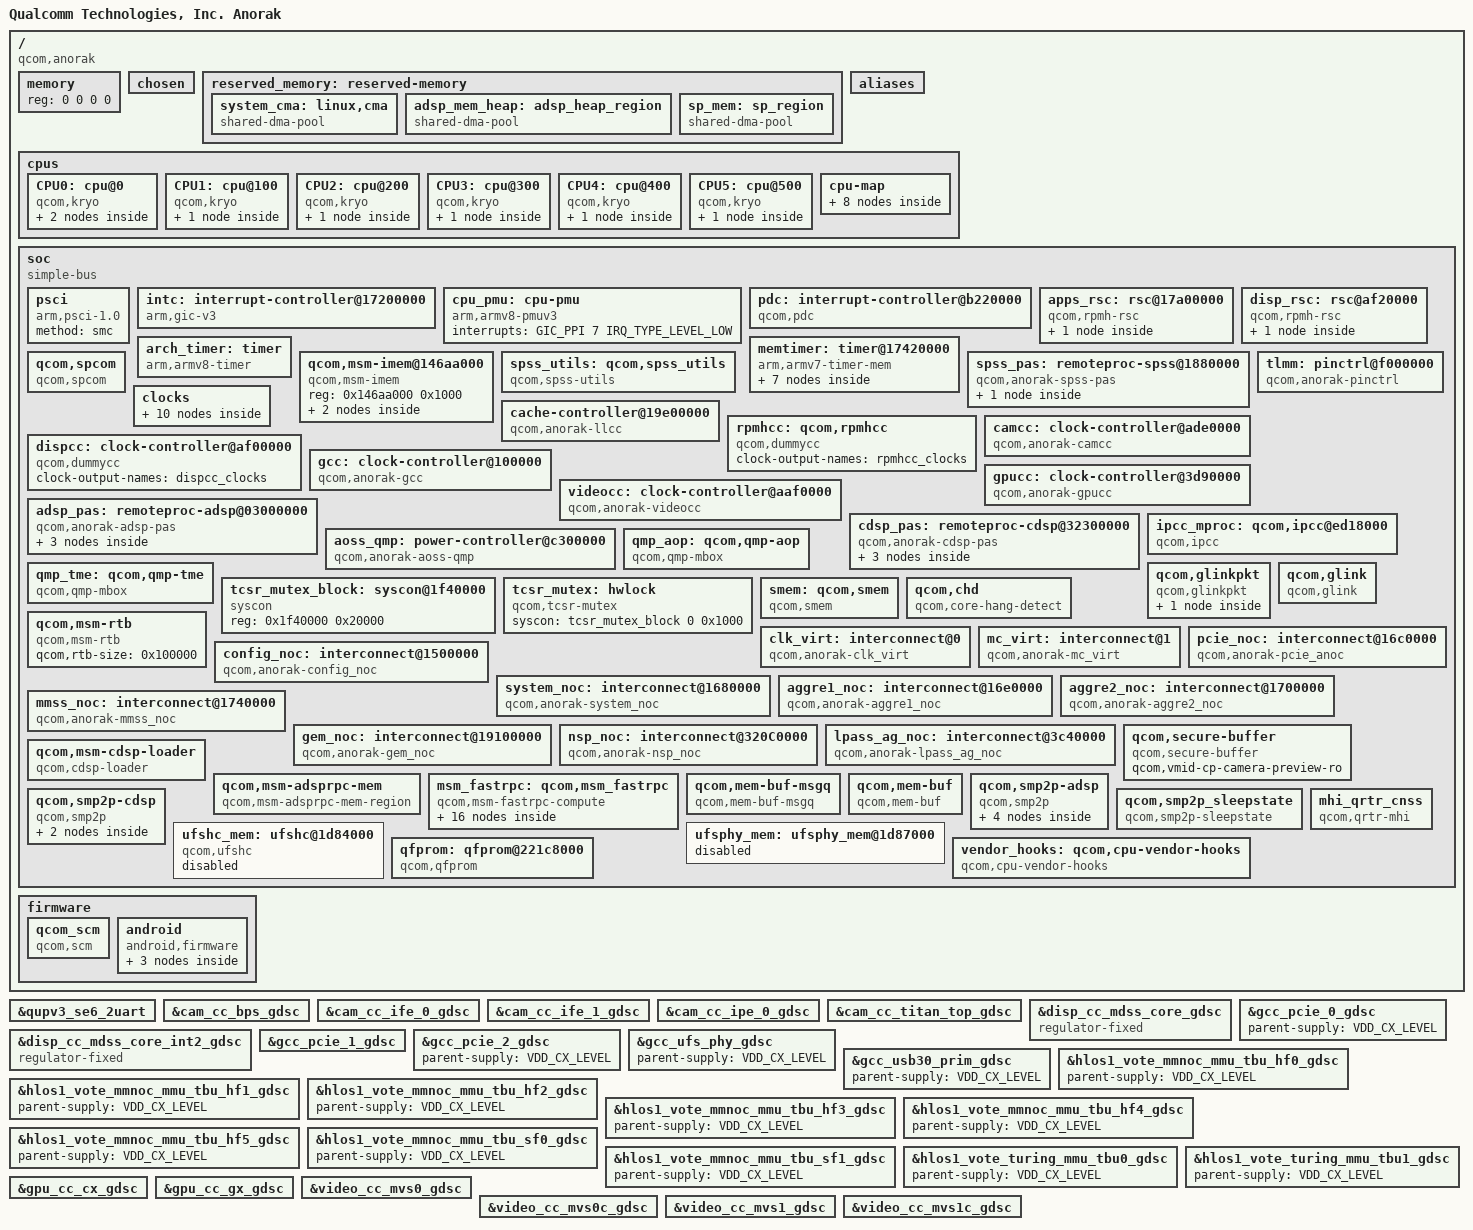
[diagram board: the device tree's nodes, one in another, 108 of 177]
#include <dt-bindings/clock/qcom,rpmh.h>
#include <dt-bindings/clock/qcom,camcc-anorak.h>
#include <dt-bindings/clock/qcom,dispcc-anorak.h>
#include <dt-bindings/clock/qcom,gcc-anorak.h>
#include <dt-bindings/clock/qcom,gpucc-anorak.h>
#include <dt-bindings/clock/qcom,videocc-anorak.h>
#include <dt-bindings/interrupt-controller/arm-gic.h>
#include <dt-bindings/interconnect/qcom,icc.h>
#include <dt-bindings/interconnect/qcom,anorak.h>
#include <dt-bindings/soc/qcom,ipcc.h>
#include <dt-bindings/soc/qcom,rpmh-rsc.h>
#include <dt-bindings/gpio/gpio.h>
#include <dt-bindings/regulator/qcom,rpmh-regulator-levels.h>

/ {
	model = "Qualcomm Technologies, Inc. Anorak";
	compatible = "qcom,anorak";
	qcom,msm-id = <549 0x10000>;
	interrupt-parent = <&intc>;

	#address-cells = <2>;
	#size-cells = <2>;
	memory { device_type = "memory"; reg = <0 0 0 0>; };


	chosen: chosen {
		bootargs = "console=ttyMSM0,115200n8 earlycon=msm_geni_serial,0x00998000 loglevel=8 log_buf_len=256K kernel.panic_on_rcu_stall=1 loop.max_part=7 service_locator.enable=1 msm_rtb.filter=0x237 allow_mismatched_32bit_el0 kasan=off rcupdate.rcu_expedited=1 rcu_nocbs=0-5 ftrace_dump_on_oops pstore.compress=none kpti=off swiotlb=noforce cgroup.memory=nokmem,nosocket allow_file_spec_access disable_dma32=on";
	};

	reserved_memory: reserved-memory { };

	aliases {
		ufshc1 = &ufshc_mem; /* Embedded UFS Slot */
		serial0 = &qupv3_se6_2uart;
	};

	cpus {
		#address-cells = <2>;
		#size-cells = <0>;

		CPU0: cpu@0 {
			device_type = "cpu";
			compatible = "qcom,kryo";
			reg = <0x0 0x0>;
			enable-method = "psci";
			next-level-cache = <&L2_0>;
			L2_0: l2-cache {
			      compatible = "arm,arch-cache";
			      cache-level = <2>;
			      next-level-cache = <&L3_0>;

				L3_0: l3-cache {
					compatible = "arm,arch-cache";
					cache-level = <3>;
				};
			};
		};

		CPU1: cpu@100 {
			device_type = "cpu";
			compatible = "qcom,kryo";
			reg = <0x0 0x100>;
			enable-method = "psci";
			next-level-cache = <&L2_1>;
			L2_1: l2-cache {
			      compatible = "arm,arch-cache";
			      cache-level = <2>;
			      next-level-cache = <&L3_0>;
			};

		};

		CPU2: cpu@200 {
			device_type = "cpu";
			compatible = "qcom,kryo";
			reg = <0x0 0x200>;
			enable-method = "psci";
			next-level-cache = <&L2_2>;
			L2_2: l2-cache {
			      compatible = "arm,arch-cache";
			      cache-level = <2>;
			      next-level-cache = <&L3_0>;
			};
		};

		CPU3: cpu@300 {
			device_type = "cpu";
			compatible = "qcom,kryo";
			reg = <0x0 0x300>;
			enable-method = "psci";
			next-level-cache = <&L2_3>;
			L2_3: l2-cache {
			      compatible = "arm,arch-cache";
			      cache-level = <2>;
			      next-level-cache = <&L3_0>;
			};

		};

		CPU4: cpu@400 {
			device_type = "cpu";
			compatible = "qcom,kryo";
			reg = <0x0 0x400>;
			enable-method = "psci";
			next-level-cache = <&L2_4>;
			L2_4: l2-cache {
				compatible = "arm,arch-cache";
				cache-level = <2>;
				next-level-cache = <&L3_0>;
			};
		};

		CPU5: cpu@500 {
			device_type = "cpu";
			compatible = "qcom,kryo";
			reg = <0x0 0x500>;
			enable-method = "psci";
			next-level-cache = <&L2_5>;
			L2_5: l2-cache {
				compatible = "arm,arch-cache";
				cache-level = <2>;
				next-level-cache = <&L3_0>;
			};
		};

		cpu-map {
			cluster0 {
				core0 {
					cpu = <&CPU0>;
				};

				core1 {
					cpu = <&CPU1>;
				};
			};

			cluster1 {
				core0 {
					cpu = <&CPU2>;
				};

				core1 {
					cpu = <&CPU3>;
				};

				core2 {
					cpu = <&CPU4>;
				};

				core3 {
					cpu = <&CPU5>;
				};
			};
		};
	};

	soc: soc { };

	firmware: firmware { };
};

#include "anorak-reserved-memory.dtsi"

&reserved_memory {
	#address-cells = <2>;
	#size-cells = <2>;
	ranges;

	/* global autoconfigured region for contiguous allocations */
	system_cma: linux,cma {
		compatible = "shared-dma-pool";
		alloc-ranges = <0x0 0x00000000 0x0 0xffffffff>;
		reusable;
		alignment = <0x0 0x400000>;
		size = <0x0 0x2000000>;
		linux,cma-default;
	};

	adsp_mem_heap: adsp_heap_region {
		compatible = "shared-dma-pool";
		alloc-ranges = <0x0 0x00000000 0x0 0xffffffff>;
		reusable;
		alignment = <0x0 0x400000>;
		size = <0x0 0xC00000>;
	};

	sp_mem: sp_region {  /* SPSS-HLOS ION shared mem */
		compatible = "shared-dma-pool";
		alloc-ranges = <0x0 0x00000000 0x0 0xffffffff>;
		reusable;
		alignment = <0x0 0x400000>;
		size = <0x0 0x1000000>;
	};
};

&firmware {
	qcom_scm {
		compatible = "qcom,scm";
	};

	android {
		compatible = "android,firmware";
		vbmeta {
			compatible = "android,vbmeta";
			parts = "vbmeta,boot,system,vendor,dtbo,recovery";
		};

		fstab {
			compatible = "android,fstab";
			vendor {
				compatible = "android,vendor";
				dev = "/dev/block/platform/soc/1d84000.ufshc/by-name/vendor";
				type = "ext4";
				mnt_flags = "ro,barrier=1,discard";
				fsmgr_flags = "wait,slotselect";
				status = "ok";
			};
		};
	};
};

&soc {
	#address-cells = <1>;
	#size-cells = <1>;
	ranges = <0 0 0 0xffffffff>;
	compatible = "simple-bus";

	psci {
		compatible = "arm,psci-1.0";
		method = "smc";
	};

	intc: interrupt-controller@17200000 {
		compatible = "arm,gic-v3";
		#interrupt-cells = <3>;
		interrupt-controller;
		#redistributor-regions = <1>;
		redistributor-stride = <0x0 0x20000>;
		reg = <0x17200000 0x10000>,	/* GICD */
		      <0x17260000 0x100000>;	/* GICR * 8 */
		interrupts = <GIC_PPI 9 IRQ_TYPE_LEVEL_LOW>;
	};

	cpu_pmu: cpu-pmu {
		compatible = "arm,armv8-pmuv3";
		interrupts = <GIC_PPI 7 IRQ_TYPE_LEVEL_LOW>;
	};

	pdc: interrupt-controller@b220000 {
		compatible = "qcom,pdc";
		reg = <0xb220000 0x30000>, <0x174000f0 0x64>;
		reg-names = "pdc-interrupt-base", "apss-shared-spi-cfg";
		qcom,pdc-ranges = <0 480 12>, <14 494 24>, <40 520 54>,
				  <94 609 31>, <125 63 1>, <126 716 12>;
		#interrupt-cells = <2>;
		interrupt-parent = <&intc>;
		interrupt-controller;
	};

	apps_rsc: rsc@17a00000 {
		label = "apps_rsc";
		compatible = "qcom,rpmh-rsc";
		reg = <0x17a00000 0x10000>,
		      <0x17a10000 0x10000>,
		      <0x17a20000 0x10000>,
		      <0x17a30000 0x10000>;
		reg-names = "drv-0", "drv-1", "drv-2", "drv-3";
		interrupts = <GIC_SPI 3 IRQ_TYPE_LEVEL_HIGH>,
			     <GIC_SPI 4 IRQ_TYPE_LEVEL_HIGH>,
			     <GIC_SPI 5 IRQ_TYPE_LEVEL_HIGH>;
			     /* No interrupt into GIC for DRV3 */
		qcom,tcs-offset = <0xd00>;
		qcom,drv-id = <2>;
		qcom,tcs-config = <ACTIVE_TCS    2>,
				  <SLEEP_TCS     3>,
				  <WAKE_TCS      3>,
				  <FAST_PATH_TCS 0>,
				  <CONTROL_TCS   0>; /* PDC wakeup values will be written from TZ */

		apps_bcm_voter: bcm_voter {
			compatible = "qcom,bcm-voter";
		};
	};

	disp_rsc: rsc@af20000 {
		label = "disp_rsc";
		compatible = "qcom,rpmh-rsc";
		reg = <0xaf20000 0x10000>;
		reg-names = "drv-0";
		interrupts = <GIC_SPI 129 IRQ_TYPE_LEVEL_HIGH>;
		clocks = <&dispcc DISP_CC_MDSS_RSCC_AHB_CLK>;
		qcom,tcs-offset = <0x1c00>;
		qcom,drv-id = <0>;
		qcom,tcs-config = <ACTIVE_TCS    0>,
				  <SLEEP_TCS     1>,
				  <WAKE_TCS      1>,
				  <CONTROL_TCS   0>,
				  <FAST_PATH_TCS 0>;

		disp_bcm_voter: bcm_voter {
			compatible = "qcom,bcm-voter";
			qcom,tcs-wait = <QCOM_ICC_TAG_AMC>;
		};
	};

	arch_timer: timer {
		compatible = "arm,armv8-timer";
		interrupts = <GIC_PPI 13 (GIC_CPU_MASK_SIMPLE(8) | IRQ_TYPE_LEVEL_LOW)>,
			     <GIC_PPI 14 (GIC_CPU_MASK_SIMPLE(8) | IRQ_TYPE_LEVEL_LOW)>,
			     <GIC_PPI 11 (GIC_CPU_MASK_SIMPLE(8) | IRQ_TYPE_LEVEL_LOW)>,
			     <GIC_PPI 12 (GIC_CPU_MASK_SIMPLE(8) | IRQ_TYPE_LEVEL_LOW)>;
		clock-frequency = <19200000>;
	};

	memtimer: timer@17420000 {
		#address-cells = <1>;
		#size-cells = <1>;
		ranges;
		compatible = "arm,armv7-timer-mem";
		reg = <0x17420000 0x1000>;
		clock-frequency = <19200000>;

		frame@17421000 {
			frame-number = <0>;
			interrupts = <GIC_SPI 8 IRQ_TYPE_LEVEL_HIGH>,
				     <GIC_SPI 6 IRQ_TYPE_LEVEL_HIGH>;
			reg = <0x17421000 0x1000>,
			      <0x17422000 0x1000>;
		};

		frame@17423000 {
			frame-number = <1>;
			interrupts = <GIC_SPI 9 IRQ_TYPE_LEVEL_HIGH>;
			reg = <0x17423000 0x1000>;
			status = "disabled";
		};

		frame@17425000 {
			frame-number = <2>;
			interrupts = <GIC_SPI 10 IRQ_TYPE_LEVEL_HIGH>;
			reg = <0x17425000 0x1000>;
			status = "disabled";
		};

		frame@17427000 {
			frame-number = <3>;
			interrupts = <GIC_SPI 11 IRQ_TYPE_LEVEL_HIGH>;
			reg = <0x17427000 0x1000>;
			status = "disabled";
		};

		frame@17429000 {
			frame-number = <4>;
			interrupts = <GIC_SPI 12 IRQ_TYPE_LEVEL_HIGH>;
			reg = <0x17429000 0x1000>;
			status = "disabled";
		};

		frame@1742b000 {
			frame-number = <5>;
			interrupts = <GIC_SPI 13 IRQ_TYPE_LEVEL_HIGH>;
			reg = <0x1742b000 0x1000>;
			status = "disabled";
		};

		frame@1742d000 {
			frame-number = <6>;
			interrupts = <GIC_SPI 14 IRQ_TYPE_LEVEL_HIGH>;
			reg = <0x1742d000 0x1000>;
			status = "disabled";
		};
	};

	qcom,msm-imem@146aa000 {
		compatible = "qcom,msm-imem";
		reg = <0x146aa000 0x1000>;
		ranges = <0x0 0x146aa000 0x1000>;
		#address-cells = <1>;
		#size-cells = <1>;

		pil@94c {
			compatible = "qcom,pil-reloc-info";
			reg = <0x94c 0xc8>;
		};

		pil@6dc {
			compatible = "qcom,msm-imem-pil-disable-timeout";
			reg = <0x6dc 0x4>;
		};
	};

	/* PIL spss node - for loading Secure Processor */
	spss_pas: remoteproc-spss@1880000 {
		compatible = "qcom,anorak-spss-pas";
		ranges;
		reg = <0x188101c 0x4>,
		      <0x1881024 0x4>,
		      <0x1881028 0x4>,
		      <0x188103c 0x4>,
		      <0x1881100 0x4>,
		      <0x1882014 0x4>;
		reg-names = "sp2soc_irq_status", "sp2soc_irq_clr", "sp2soc_irq_mask",
			    "rmb_err", "rmb_general_purpose", "rmb_err_spare2";
		interrupts = <0 352 1>;

		cx-supply = <&VDD_CX_LEVEL>;
		cx-uV-uA = <RPMH_REGULATOR_LEVEL_TURBO 100000>;

		clocks = <&rpmhcc RPMH_CXO_CLK>;
		clock-names = "xo";
		qcom,proxy-clock-names = "xo";
		status = "ok";

		memory-region = <&spss_region_mem>;
		qcom,spss-scsr-bits = <24 25>;
		qcom,extra-size = <4096>;

		interconnects = <&aggre2_noc MASTER_CRYPTO &mc_virt SLAVE_EBI1>;
		interconnect-names = "crypto_ddr";

		glink-edge {
			qcom,remote-pid = <8>;
			mboxes = <&ipcc_mproc IPCC_CLIENT_SPSS
				  IPCC_MPROC_SIGNAL_GLINK_QMP>;
			mbox-names = "spss_spss";
			interrupt-parent = <&ipcc_mproc>;
			interrupts = <IPCC_CLIENT_SPSS
				      IPCC_MPROC_SIGNAL_GLINK_QMP
				      IRQ_TYPE_EDGE_RISING>;

			reg = <0x1885008 0x8>,
			      <0x1885010 0x4>;
			reg-names = "qcom,spss-addr",
				    "qcom,spss-size";

			label = "spss";
			qcom,glink-label = "spss";
		};
	};

	qcom,spcom {
		compatible = "qcom,spcom";

		qcom,rproc-handle = <&spss_pas>;
		qcom,boot-enabled;
		/* predefined channels, remote side is server */
		qcom,spcom-ch-names = "sp_kernel", "sp_ssr";
		/* sp2soc rmb shared register physical address and bmsk */
		qcom,spcom-sp2soc-rmb-reg-addr = <0x01881020>;
		qcom,spcom-sp2soc-rmb-initdone-bit = <24>;
		qcom,spcom-sp2soc-rmb-pbldone-bit = <25>;
		/* soc2sp rmb shared register physical address */
		qcom,spcom-soc2sp-rmb-reg-addr = <0x01881030>;
		qcom,spcom-soc2sp-rmb-sp-ssr-bit = <0>;
		status = "ok";
	};

	spss_utils: qcom,spss_utils {
		compatible = "qcom,spss-utils";
		/* spss fuses physical address */
		qcom,rproc-handle = <&spss_pas>;
		qcom,spss-fuse1-addr = <0x221C8214>;
		qcom,spss-fuse1-bit = <8>;
		qcom,spss-fuse2-addr = <0x221C8214>;
		qcom,spss-fuse2-bit = <7>;
		qcom,spss-dev-firmware-name  = "spss1d.mdt";  /* 8 chars max */
		qcom,spss-test-firmware-name = "spss1t.mdt";  /* 8 chars max */
		qcom,spss-prod-firmware-name = "spss1p.mdt";  /* 8 chars max */
		qcom,spss-debug-reg-addr = <0x01886020>;
		qcom,spss-debug-reg-addr1 = <0x01888020>;
		qcom,spss-debug-reg-addr3 = <0x0188C020>;
		qcom,spss-emul-type-reg-addr = <0x01fc8004>;
		pil-mem = <&spss_region_mem>;
		qcom,pil-size = <0x0F0000>; // padding to 960KB
		status = "ok";
	};

	tlmm: pinctrl@f000000 {
		compatible = "qcom,anorak-pinctrl";
		reg = <0xf000000 0x1000000>;
		interrupts = <GIC_SPI 208 IRQ_TYPE_LEVEL_HIGH>;
		gpio-controller;
		#gpio-cells = <2>;
		interrupt-controller;
		#interrupt-cells = <2>;
		wakeup-parent = <&pdc>;
	};

	clocks {
		xo_board: xo_board {
			compatible = "fixed-clock";
			clock-frequency = <76800000>;
			clock-output-names = "xo_board";
			#clock-cells = <0>;
		};

		sleep_clk: sleep_clk {
			compatible = "fixed-clock";
			clock-frequency = <32000>;
			clock-output-names = "sleep_clk";
			#clock-cells = <0>;
		};

		pcie_0_pipe_clk: pcie_0_pipe_clk {
			compatible = "fixed-clock";
			clock-frequency = <1000>;
			clock-output-names = "pcie_0_pipe_clk";
			#clock-cells = <0>;
		};

		pcie_1_pipe_clk: pcie_1_pipe_clk {
			compatible = "fixed-clock";
			clock-frequency = <1000>;
			clock-output-names = "pcie_1_pipe_clk";
			#clock-cells = <0>;
		};

		pcie_2_phy_aux_clk: pcie_2_phy_aux_clk {
			compatible = "fixed-clock";
			clock-frequency = <1000>;
			clock-output-names = "pcie_2_phy_aux_clk";
			#clock-cells = <0>;
		};

		pcie_2_pipe_clk: pcie_2_pipe_clk {
			compatible = "fixed-clock";
			clock-frequency = <1000>;
			clock-output-names = "pcie_2_pipe_clk";
			#clock-cells = <0>;
		};

		ufs_phy_rx_symbol_0_clk: ufs_phy_rx_symbol_0_clk {
			compatible = "fixed-clock";
			clock-frequency = <1000>;
			clock-output-names = "ufs_phy_rx_symbol_0_clk";
			#clock-cells = <0>;
		};

		ufs_phy_rx_symbol_1_clk: ufs_phy_rx_symbol_1_clk {
			compatible = "fixed-clock";
			clock-frequency = <1000>;
			clock-output-names = "ufs_phy_rx_symbol_1_clk";
			#clock-cells = <0>;
		};

		ufs_phy_tx_symbol_0_clk: ufs_phy_tx_symbol_0_clk {
			compatible = "fixed-clock";
			clock-frequency = <1000>;
			clock-output-names = "ufs_phy_tx_symbol_0_clk";
			#clock-cells = <0>;
		};

		usb3_phy_wrapper_gcc_usb30_pipe_clk: usb3_phy_wrapper_gcc_usb30_pipe_clk {
			compatible = "fixed-clock";
			clock-frequency = <1000>;
			clock-output-names = "usb3_phy_wrapper_gcc_usb30_pipe_clk";
			#clock-cells = <0>;
		};
	};

	cache-controller@19e00000 {
		compatible = "qcom,anorak-llcc", "qcom,llcc-v41";
		reg = <0x19e00000 0x800000>, <0x1a600000 0x200000>;
		reg-names = "llcc_base", "llcc_broadcast_base";
		interrupts = <GIC_SPI 266 IRQ_TYPE_LEVEL_HIGH>;
		cap-based-alloc-and-pwr-collapse;
	};

	rpmhcc: qcom,rpmhcc {
		compatible = "qcom,dummycc";
		clock-output-names = "rpmhcc_clocks";
		#clock-cells = <1>;
		#reset-cells = <1>;
	};

	camcc: clock-controller@ade0000 {
		compatible = "qcom,anorak-camcc", "syscon";
		reg = <0xade0000 0x20000>;
		reg-name = "cc_base";
		vdd_mm-supply = <&VDD_MM_LEVEL>;
		vdd_mxa-supply = <&VDD_MXA_LEVEL>;
		vdd_mxc-supply = <&VDD_MXC_LEVEL>;
		clocks = <&rpmhcc RPMH_CXO_CLK>,
			<&sleep_clk>,
			<&gcc GCC_CAMERA_AHB_CLK>;
		clock-names = "bi_tcxo",
			"sleep_clk","iface";
		clock-output-names = "camcc_clocks";
		#clock-cells = <1>;
		#reset-cells = <1>;
	};

	dispcc: clock-controller@af00000 {
		compatible = "qcom,dummycc";
		clock-output-names = "dispcc_clocks";
		#clock-cells = <1>;
		#reset-cells = <1>;
	};

	gcc: clock-controller@100000 {
		compatible = "qcom,anorak-gcc", "syscon";
		reg = <0x100000 0x1f4200>;
		reg-name = "cc_base";
		vdd_cx-supply = <&VDD_CX_LEVEL>;
		vdd_mxa-supply = <&VDD_MXA_LEVEL>;
		clocks = <&rpmhcc RPMH_CXO_CLK>, <&sleep_clk>,
			<&pcie_0_pipe_clk>, <&pcie_1_pipe_clk>,
			<&pcie_2_phy_aux_clk>, <&pcie_2_pipe_clk>,
			<&ufs_phy_rx_symbol_0_clk>, <&ufs_phy_rx_symbol_1_clk>,
			<&ufs_phy_tx_symbol_0_clk>, <&usb3_phy_wrapper_gcc_usb30_pipe_clk>;
		clock-names = "bi_tcxo", "sleep_clk",
			"pcie_0_pipe_clk", "pcie_1_pipe_clk",
			"pcie_2_phy_aux_clk", "pcie_2_pipe_clk",
			"ufs_phy_rx_symbol_0_clk", "ufs_phy_rx_symbol_1_clk",
			"ufs_phy_tx_symbol_0_clk", "usb3_phy_wrapper_gcc_usb30_pipe_clk";
		#clock-cells = <1>;
		#reset-cells = <1>;
	};

	gpucc: clock-controller@3d90000 {
		compatible = "qcom,anorak-gpucc", "syscon";
		reg = <0x3d90000 0xa000>;
		reg-name = "cc_base";
		vdd_cx-supply = <&VDD_CX_LEVEL>;
		vdd_mxa-supply = <&VDD_MXA_LEVEL>;
		vdd_mxc-supply = <&VDD_MXC_LEVEL>;
		clocks = <&rpmhcc RPMH_CXO_CLK>, <&gcc GCC_GPU_GPLL0_CLK_SRC>,
			<&gcc GCC_GPU_GPLL0_DIV_CLK_SRC>;
		clock-names = "bi_tcxo", "gpll0_out_main",
			"gpll0_out_main_div";
		#clock-cells = <1>;
		#reset-cells = <1>;
	};

	videocc: clock-controller@aaf0000 {
		compatible = "qcom,anorak-videocc", "syscon";
		reg = <0xaaf0000 0x10000>;
		reg-name = "cc_base";
		vdd_mm-supply = <&VDD_MM_LEVEL>;
		vdd_mxc-supply = <&VDD_MXC_LEVEL>;
		clocks = <&rpmhcc RPMH_CXO_CLK>,
			<&sleep_clk>,
			<&gcc GCC_VIDEO_AHB_CLK>;
		clock-names = "bi_tcxo", "sleep_clk",
			"iface";
		#clock-cells = <1>;
		#reset-cells = <1>;
	};

	adsp_pas: remoteproc-adsp@03000000 {
		compatible = "qcom,anorak-adsp-pas";
		reg = <0x03000000 0x10000>;

		cx-supply = <&VDD_LPI_CX_LEVEL>;
		cx-uV-uA = <RPMH_REGULATOR_LEVEL_TURBO 0>;
		mx-supply = <&VDD_LPI_MX_LEVEL>;
		mx-uV-uA = <RPMH_REGULATOR_LEVEL_TURBO 0>;
		reg-names = "cx", "mx";

		clocks = <&rpmhcc RPMH_CXO_CLK>;
		clock-names = "xo";

		qcom,qmp = <&aoss_qmp>;

		memory-region = <&adsp_mem>;

		/* Inputs from ssc */
		interrupts-extended = <&pdc 6 IRQ_TYPE_EDGE_RISING>,
					<&adsp_smp2p_in 0 0>,
					<&adsp_smp2p_in 2 0>,
					<&adsp_smp2p_in 1 0>,
					<&adsp_smp2p_in 3 0>;

		interrupt-names = "wdog",
				"fatal",
				"handover",
				"ready",
				"stop-ack";

		/* Outputs to turing */
		qcom,smem-states = <&adsp_smp2p_out 0>;
		qcom,smem-state-names = "stop";

		status = "ok";

		glink_edge: glink-edge {
			qcom,remote-pid = <2>;
			transport = "smem";
			mboxes = <&ipcc_mproc IPCC_CLIENT_LPASS
			IPCC_MPROC_SIGNAL_GLINK_QMP>;
			mbox-names = "adsp_smem";
			interrupt-parent = <&ipcc_mproc>;
			interrupts = <IPCC_CLIENT_LPASS
					IPCC_MPROC_SIGNAL_GLINK_QMP
					IRQ_TYPE_EDGE_RISING>;

			label = "adsp";
			qcom,glink-label = "lpass";

			qcom,adsp_qrtr {
				qcom,glink-channels = "IPCRTR";
				qcom,intents = <0x800  5
						0x2000 3
						0x4400 2>;
			};

			qcom,msm_fastrpc_rpmsg {
					compatible = "qcom,msm-fastrpc-rpmsg";
					qcom,glink-channels = "fastrpcglink-apps-dsp";
					qcom,intents = <0x64 64>;
			};
		};
	};

	cdsp_pas: remoteproc-cdsp@32300000 {
		compatible = "qcom,anorak-cdsp-pas";
		reg = <0x32300000 0x10000>;

		cx-supply = <&VDD_CX_LEVEL>;
		cx-uV-uA = <RPMH_REGULATOR_LEVEL_TURBO 100000>;
		mx-supply = <&VDD_MXC_LEVEL>;
		mx-uV-uA = <RPMH_REGULATOR_LEVEL_TURBO 100000>;
		reg-names = "cx","mx","nsp";
		clocks = <&rpmhcc RPMH_CXO_CLK>;
		clock-names = "xo";

		qcom,qmp = <&aoss_qmp>;

		memory-region = <&cdsp_mem>;

		/* Inputs from turing */
		interrupts-extended = <&intc GIC_SPI 578 IRQ_TYPE_EDGE_RISING>,
					<&cdsp_smp2p_in 0 0>,
					<&cdsp_smp2p_in 2 0>,
					<&cdsp_smp2p_in 1 0>,
					<&cdsp_smp2p_in 3 0>;

		interrupt-names = "wdog",
				"fatal",
				"handover",
				"ready",
				"stop-ack";

		/* Outputs to turing */
		qcom,smem-states = <&cdsp_smp2p_out 0>;
		qcom,smem-state-names = "stop";
		status = "ok";

		glink-edge {
			qcom,remote-pid = <5>;
			transport = "smem";
			mboxes = <&ipcc_mproc IPCC_CLIENT_CDSP
					  IPCC_MPROC_SIGNAL_GLINK_QMP>;
			mbox-names = "cdsp_smem";
			interrupt-parent = <&ipcc_mproc>;
			interrupts = <IPCC_CLIENT_CDSP
				  IPCC_MPROC_SIGNAL_GLINK_QMP
				  IRQ_TYPE_EDGE_RISING>;

			label = "cdsp";
			qcom,glink-label = "cdsp";

			qcom,cdsp_qrtr {
				qcom,glink-channels = "IPCRTR";
				qcom,intents = <0x800  5
						0x2000 3
						0x4400 2>;
			};

			qcom,msm_fastrpc_rpmsg {
				compatible = "qcom,msm-fastrpc-rpmsg";
				qcom,glink-channels = "fastrpcglink-apps-dsp";
				qcom,intents = <0x64 64>;
			};
		};
	};

	ipcc_mproc: qcom,ipcc@ed18000 {
		compatible = "qcom,ipcc";
		reg = <0x408000 0x1000>;
		interrupts = <GIC_SPI 229 IRQ_TYPE_LEVEL_HIGH>;
		interrupt-controller;
		#interrupt-cells = <3>;
		#mbox-cells = <2>;
	};

	aoss_qmp: power-controller@c300000 {
		compatible = "qcom,anorak-aoss-qmp";
		reg = <0xc300000 0x400>;
		interrupt-parent = <&ipcc_mproc>;
		interrupts = <IPCC_CLIENT_AOP
				IPCC_MPROC_SIGNAL_GLINK_QMP
				IRQ_TYPE_EDGE_RISING>;
		mboxes = <&ipcc_mproc IPCC_CLIENT_AOP
		IPCC_MPROC_SIGNAL_GLINK_QMP>;

		#power-domain-cells = <1>;
		#clock-cells = <0>;
	};

	qmp_aop: qcom,qmp-aop {
		compatible = "qcom,qmp-mbox";
		qcom,qmp = <&aoss_qmp>;
		label = "aop";
		#mbox-cells = <1>;
	};

	qmp_tme: qcom,qmp-tme {
		compatible = "qcom,qmp-mbox";
		qcom,remote-pid = <14>;
		mboxes = <&ipcc_mproc IPCC_CLIENT_TME
				IPCC_MPROC_SIGNAL_GLINK_QMP>;
		mbox-names = "tme_qmp";
		interrupt-parent = <&ipcc_mproc>;
		interrupts = <IPCC_CLIENT_TME
				IPCC_MPROC_SIGNAL_GLINK_QMP
				IRQ_TYPE_EDGE_RISING>;

		label = "tme";
		qcom,early-boot;
		priority = <0>;
		mbox-desc-offset = <0x0>;
		#mbox-cells = <1>;
	};

	qcom,glinkpkt {
		compatible = "qcom,glinkpkt";

		qcom,glinkpkt-apr-apps2 {
			qcom,glinkpkt-edge = "adsp";
			qcom,glinkpkt-ch-name = "apr_apps2";
			qcom,glinkpkt-dev-name = "apr_apps2";
		};
	};

	qcom,glink {
		compatible = "qcom,glink";
	};

	tcsr_mutex_block: syscon@1f40000 {
		compatible = "syscon";
		reg = <0x1f40000 0x20000>;
	};

	tcsr_mutex: hwlock {
		compatible = "qcom,tcsr-mutex";
		syscon = <&tcsr_mutex_block 0 0x1000>;
		#hwlock-cells = <1>;
		};

	smem: qcom,smem {
		compatible = "qcom,smem";
		memory-region = <&smem_mem>;
		hwlocks = <&tcsr_mutex 3>;
	};

	qcom,chd {
		compatible = "qcom,core-hang-detect";
		label = "core";
		qcom,threshold-arr = <0x17800058 0x17810058 0x17820058 0x17830058 0x17840058 0x17850058>;
		qcom,config-arr =<0x17800060 0x17810060 0x17820060 0x17830060 0x17840060 0x17850060>;
	};

	qcom,msm-rtb {
		compatible = "qcom,msm-rtb";
		qcom,rtb-size = <0x100000>;
	};

	clk_virt: interconnect@0 {
		compatible = "qcom,anorak-clk_virt";
		#interconnect-cells = <1>;
		qcom,bcm-voter-names = "hlos";
		qcom,bcm-voters = <&apps_bcm_voter>;
	};

	mc_virt: interconnect@1 {
		compatible = "qcom,anorak-mc_virt";
		#interconnect-cells = <1>;
		qcom,bcm-voter-names = "hlos", "disp";
		qcom,bcm-voters = <&apps_bcm_voter>, <&disp_bcm_voter>;
	};

	config_noc: interconnect@1500000 {
		reg = <0x1500000 0x13080>;
		compatible = "qcom,anorak-config_noc";
		#interconnect-cells = <1>;
		qcom,bcm-voter-names = "hlos";
		qcom,bcm-voters = <&apps_bcm_voter>;
	};

	system_noc: interconnect@1680000 {
		reg = <0x01680000 0x13080>;
		compatible = "qcom,anorak-system_noc";
		#interconnect-cells = <1>;
		qcom,bcm-voter-names = "hlos";
		qcom,bcm-voters = <&apps_bcm_voter>;
	};

	pcie_noc: interconnect@16c0000 {
		reg = <0x16C0000 0xC080>;
		compatible = "qcom,anorak-pcie_anoc";
		#interconnect-cells = <1>;
		qcom,bcm-voter-names = "hlos";
		qcom,bcm-voters = <&apps_bcm_voter>;
	};

	aggre1_noc: interconnect@16e0000 {
		reg = <0x16E0000 0x9080>;
		compatible = "qcom,anorak-aggre1_noc";
		#interconnect-cells = <1>;
		qcom,bcm-voter-names = "hlos";
		qcom,bcm-voters = <&apps_bcm_voter>;
	};

	aggre2_noc: interconnect@1700000 {
		reg = <0x1700000 0x15080>;
		compatible = "qcom,anorak-aggre2_noc";
		#interconnect-cells = <1>;
		qcom,bcm-voter-names = "hlos";
		qcom,bcm-voters = <&apps_bcm_voter>;
	};

	mmss_noc: interconnect@1740000 {
		reg = <0x01740000 0x1C100>;
		compatible = "qcom,anorak-mmss_noc";
		#interconnect-cells = <1>;
		qcom,bcm-voter-names = "hlos", "disp";
		qcom,bcm-voters = <&apps_bcm_voter>, <&disp_bcm_voter>;
	};

	gem_noc: interconnect@19100000 {
		reg = <0x19100000 0xA9080>;
		compatible = "qcom,anorak-gem_noc";
		#interconnect-cells = <1>;
		qcom,bcm-voter-names = "hlos", "disp";
		qcom,bcm-voters = <&apps_bcm_voter>, <&disp_bcm_voter>;
	};

	nsp_noc: interconnect@320C0000 {
		reg = <0x320C0000 0x10000>;
		compatible = "qcom,anorak-nsp_noc";
		#interconnect-cells = <1>;
		qcom,bcm-voter-names = "hlos";
		qcom,bcm-voters = <&apps_bcm_voter>;
	};

	lpass_ag_noc: interconnect@3c40000 {
		reg = <0x3c40000 0x17200>;
		compatible = "qcom,anorak-lpass_ag_noc";
		#interconnect-cells = <1>;
		qcom,bcm-voter-names = "hlos";
		qcom,bcm-voters = <&apps_bcm_voter>;
	};

	qcom,secure-buffer {
		compatible = "qcom,secure-buffer";
		qcom,vmid-cp-camera-preview-ro;
	};

	qcom,msm-cdsp-loader {
		compatible = "qcom,cdsp-loader";
		qcom,proc-img-to-load = "cdsp";
		qcom,rproc-handle = <&cdsp_pas>;
	};

	qcom,msm-adsprpc-mem {
		compatible = "qcom,msm-adsprpc-mem-region";
		memory-region = <&adsp_mem_heap>;
		restrict-access;
	};

	msm_fastrpc: qcom,msm_fastrpc {
		compatible = "qcom,msm-fastrpc-compute";
		qcom,adsp-remoteheap-vmid = <22 37>;
		qcom,fastrpc-adsp-audio-pdr;
		qcom,fastrpc-adsp-sensors-pdr;
		qcom,rpc-latency-us = <235>;
		qcom,fastrpc-gids = <2908>;
		qcom,qos-cores = <2>; /* its a gold+ cluster */

		qcom,msm_fastrpc_compute_cb1 {
			compatible = "qcom,msm-fastrpc-compute-cb";
			label = "cdsprpc-smd";
			iommus = <&apps_smmu 0x0961 0x0420>,
					 <&apps_smmu 0x2021 0x0560>;
			qcom,iommu-dma-addr-pool = <0x80000000 0x78000000>;
			qcom,iommu-faults = "stall-disable", "HUPCF";
			dma-coherent;
		};

		qcom,msm_fastrpc_compute_cb2 {
			compatible = "qcom,msm-fastrpc-compute-cb";
			label = "cdsprpc-smd";
			iommus = <&apps_smmu 0x0962 0x0400>,
					 <&apps_smmu 0x2022 0x0460>;
			qcom,iommu-dma-addr-pool = <0x80000000 0x78000000>;
			qcom,iommu-faults = "stall-disable", "HUPCF";
			dma-coherent;
		};

		qcom,msm_fastrpc_compute_cb3 {
			compatible = "qcom,msm-fastrpc-compute-cb";
			label = "cdsprpc-smd";
			iommus = <&apps_smmu 0x0963 0x0C60>,
					 <&apps_smmu 0x2023 0x0420>;
			qcom,iommu-dma-addr-pool = <0x80000000 0x78000000>;
			qcom,iommu-faults = "stall-disable", "HUPCF";
			dma-coherent;
		};

		qcom,msm_fastrpc_compute_cb4 {
			compatible = "qcom,msm-fastrpc-compute-cb";
			label = "cdsprpc-smd";
			iommus = <&apps_smmu 0x0964 0x0560>,
					 <&apps_smmu 0x2024 0x2420>;
			qcom,iommu-dma-addr-pool = <0x80000000 0x78000000>;
			qcom,iommu-faults = "stall-disable", "HUPCF";
			dma-coherent;
		};

		qcom,msm_fastrpc_compute_cb5 {
			compatible = "qcom,msm-fastrpc-compute-cb";
			label = "cdsprpc-smd";
			iommus = <&apps_smmu 0x0965 0x0540>,
					 <&apps_smmu 0x2025 0x0520>;
			qcom,iommu-dma-addr-pool = <0x80000000 0x78000000>;
			qcom,iommu-faults = "stall-disable", "HUPCF";
			dma-coherent;
		};

		qcom,msm_fastrpc_compute_cb6 {
			compatible = "qcom,msm-fastrpc-compute-cb";
			label = "cdsprpc-smd";
			iommus = <&apps_smmu 0x0966 0x0440>,
					 <&apps_smmu 0x2026 0x2520>;
			qcom,iommu-dma-addr-pool = <0x80000000 0x78000000>;
			qcom,iommu-faults = "stall-disable", "HUPCF";
			dma-coherent;
		};

		qcom,msm_fastrpc_compute_cb7 {
			compatible = "qcom,msm-fastrpc-compute-cb";
			label = "cdsprpc-smd";
			iommus = <&apps_smmu 0x0967 0x0520>,
					 <&apps_smmu 0x2027 0x0560>;
			qcom,iommu-dma-addr-pool = <0x80000000 0x78000000>;
			qcom,iommu-faults = "stall-disable", "HUPCF";
			dma-coherent;
		};

		qcom,msm_fastrpc_compute_cb8 {
			compatible = "qcom,msm-fastrpc-compute-cb";
			label = "cdsprpc-smd";
			iommus = <&apps_smmu 0x0968 0x0440>,
					 <&apps_smmu 0x2028 0x0420>;
			qcom,iommu-dma-addr-pool = <0x80000000 0x78000000>;
			qcom,iommu-faults = "stall-disable", "HUPCF";
			dma-coherent;
		};

		qcom,msm_fastrpc_compute_cb9 {
			compatible = "qcom,msm-fastrpc-compute-cb";
			label = "cdsprpc-smd";
			qcom,secure-context-bank;
			iommus = <&apps_smmu 0x0969 0x0560>,
					 <&apps_smmu 0x2029 0x2520>;
			qcom,iommu-dma-addr-pool = <0x60000000 0x78000000>;
			qcom,iommu-faults = "stall-disable", "HUPCF";
			qcom,iommu-vmid = <0xA>;	/* VMID_CP_PIXEL */
			dma-coherent;
		};

		qcom,msm_fastrpc_compute_cb10 {
			compatible = "qcom,msm-fastrpc-compute-cb";
			label = "adsprpc-smd";
			iommus = <&apps_smmu 0x2803 0x0>;
			qcom,iommu-dma-addr-pool = <0x80000000 0x78000000>;
			qcom,iommu-faults = "stall-disable", "HUPCF";
			dma-coherent;
		};

		qcom,msm_fastrpc_compute_cb11 {
			compatible = "qcom,msm-fastrpc-compute-cb";
			label = "adsprpc-smd";
			iommus = <&apps_smmu 0x2804 0x0>;
			qcom,iommu-dma-addr-pool = <0x80000000 0x78000000>;
			qcom,iommu-faults = "stall-disable", "HUPCF";
			dma-coherent;
		};

		qcom,msm_fastrpc_compute_cb12 {
			compatible = "qcom,msm-fastrpc-compute-cb";
			label = "adsprpc-smd";
			iommus = <&apps_smmu 0x2805 0x0>;
			qcom,iommu-dma-addr-pool = <0x80000000 0x78000000>;
			qcom,iommu-faults = "stall-disable", "HUPCF";
			dma-coherent;
			shared-cb = <5>;
		};

		qcom,msm_fastrpc_compute_cb13 {
			compatible = "qcom,msm-fastrpc-compute-cb";
			label = "cdsprpc-smd";
			iommus = <&apps_smmu 0x096B 0x0400>,
					 <&apps_smmu 0x202B 0x2420>;
			qcom,iommu-dma-addr-pool = <0x80000000 0x78000000>;
			qcom,iommu-faults = "stall-disable", "HUPCF";
			dma-coherent;
		};

		qcom,msm_fastrpc_compute_cb14 {
			compatible = "qcom,msm-fastrpc-compute-cb";
			label = "cdsprpc-smd";
			iommus = <&apps_smmu 0x096C 0x0C60>,
					 <&apps_smmu 0x202C 0x0460>;
			qcom,iommu-dma-addr-pool = <0x80000000 0x78000000>;
			qcom,iommu-faults = "stall-disable", "HUPCF";
			dma-coherent;
		};

		qcom,msm_fastrpc_compute_cb15 {
			compatible = "qcom,msm-fastrpc-compute-cb";
			label = "cdsprpc-smd";
			iommus = <&apps_smmu 0x096D 0x0D00>,
					 <&apps_smmu 0x202D 0x2420>;
			qcom,iommu-dma-addr-pool = <0x80000000 0x78000000>;
			qcom,iommu-faults = "stall-disable", "HUPCF";
			dma-coherent;
		};

		qcom,msm_fastrpc_compute_cb16 {
			compatible = "qcom,msm-fastrpc-compute-cb";
			label = "cdsprpc-smd";
			iommus = <&apps_smmu 0x096E 0x0560>,
					 <&apps_smmu 0x202E 0x0460>;
			qcom,iommu-dma-addr-pool = <0x80000000 0x78000000>;
			qcom,iommu-faults = "stall-disable", "HUPCF";
			dma-coherent;
		};
	};

	qcom,mem-buf-msgq {
		compatible = "qcom,mem-buf-msgq";
	};

	qcom,mem-buf {
		compatible = "qcom,mem-buf";
		qcom,mem-buf-capabilities = "supplier";
		qcom,vmid = <3>;
	};

	qcom,smp2p-adsp {
		compatible = "qcom,smp2p";
		qcom,smem = <443>, <429>;
		interrupt-parent = <&ipcc_mproc>;
		interrupts = <IPCC_CLIENT_LPASS IPCC_MPROC_SIGNAL_SMP2P
			      IRQ_TYPE_EDGE_RISING>;
		mboxes = <&ipcc_mproc IPCC_CLIENT_LPASS
			  IPCC_MPROC_SIGNAL_SMP2P>;
		qcom,local-pid = <0>;
		qcom,remote-pid = <2>;

		adsp_smp2p_out: master-kernel {
			qcom,entry-name = "master-kernel";
			#qcom,smem-state-cells = <1>;
		};

		adsp_smp2p_in: slave-kernel {
			qcom,entry-name = "slave-kernel";
			interrupt-controller;
			#interrupt-cells = <2>;
		};

		sleepstate_smp2p_out: sleepstate-out {
			qcom,entry-name = "sleepstate";
			#qcom,smem-state-cells = <1>;
		};

		sleepstate_smp2p_in: qcom,sleepstate-in {
			qcom,entry-name = "sleepstate_see";
			interrupt-controller;
			#interrupt-cells = <2>;
		};
	};

	qcom,smp2p-cdsp {
		compatible = "qcom,smp2p";
		qcom,smem = <94>, <432>;
		interrupt-parent = <&ipcc_mproc>;
		interrupts = <IPCC_CLIENT_CDSP IPCC_MPROC_SIGNAL_SMP2P
			      IRQ_TYPE_EDGE_RISING>;
		mboxes = <&ipcc_mproc IPCC_CLIENT_CDSP IPCC_MPROC_SIGNAL_SMP2P>;
		qcom,local-pid = <0>;
		qcom,remote-pid = <5>;

		cdsp_smp2p_out: master-kernel {
			qcom,entry-name = "master-kernel";
			#qcom,smem-state-cells = <1>;
		};

		cdsp_smp2p_in: slave-kernel {
			qcom,entry-name = "slave-kernel";
			interrupt-controller;
			#interrupt-cells = <2>;
		};
	};

	qcom,smp2p_sleepstate {
		compatible = "qcom,smp2p-sleepstate";
		qcom,smem-states = <&sleepstate_smp2p_out 0>;
		interrupt-parent = <&sleepstate_smp2p_in>;
		interrupts = <0 0>;
		interrupt-names = "smp2p-sleepstate-in";
	};

	mhi_qrtr_cnss {
		compatible = "qcom,qrtr-mhi";
		qcom,dev-id = <0x1103>;
		qcom,net-id = <0>;
		qcom,low-latency;
	};


	ufsphy_mem: ufsphy_mem@1d87000 {
		reg = <0x1d87000 0xe10>;
		reg-names = "phy_mem";
		#phy-cells = <0>;

		lanes-per-direction = <2>;
		clock-names = "ref_clk_src",
			"ref_aux_clk",
			"qref_clk";
		clocks = <&rpmhcc RPMH_CXO_CLK>,
			<&gcc GCC_UFS_PHY_PHY_AUX_CLK>,
			<&gcc GCC_UFS_0_CLKREF_EN>;
		resets = <&ufshc_mem 0>;
		status = "disabled";
	};

	ufshc_mem: ufshc@1d84000 {
		compatible = "qcom,ufshc";
		reg = <0x1d84000 0x3000>;
		reg-names = "ufs_mem";
		interrupts = <GIC_SPI 265 IRQ_TYPE_LEVEL_HIGH>;
		phys = <&ufsphy_mem>;
		phy-names = "ufsphy";
		#reset-cells = <1>;

		lanes-per-direction = <2>;
		dev-ref-clk-freq = <0>; /* 19.2 MHz */
		clock-names =
			"core_clk",
			"bus_aggr_clk",
			"iface_clk",
			"core_clk_unipro",
			"core_clk_ice",
			"ref_clk",
			"tx_lane0_sync_clk",
			"rx_lane0_sync_clk",
			"rx_lane1_sync_clk";
		clocks =
			<&gcc GCC_UFS_PHY_AXI_CLK>,
			<&gcc GCC_AGGRE_UFS_PHY_AXI_CLK>,
			<&gcc GCC_UFS_PHY_AHB_CLK>,
			<&gcc GCC_UFS_PHY_UNIPRO_CORE_CLK>,
			<&gcc GCC_UFS_PHY_ICE_CORE_CLK>,
			<&rpmhcc RPMH_CXO_CLK>,
			<&gcc GCC_UFS_PHY_TX_SYMBOL_0_CLK>,
			<&gcc GCC_UFS_PHY_RX_SYMBOL_0_CLK>,
			<&gcc GCC_UFS_PHY_RX_SYMBOL_1_CLK>;
		freq-table-hz =
			<75000000 300000000>,
			<0 0>,
			<0 0>,
			<75000000 300000000>,
			<75000000 300000000>,
			<0 0>,
			<0 0>,
			<0 0>,
			<0 0>;

		iommus = <&apps_smmu 0x60 0x0>;
		qcom,iommu-dma = "fastmap";
		dma-coherent;

		reset-gpios = <&tlmm 224 GPIO_ACTIVE_LOW>;
		resets = <&gcc GCC_UFS_PHY_BCR>;
		reset-names = "rst";
		status = "disabled";
	};

	vendor_hooks: qcom,cpu-vendor-hooks {
		compatible = "qcom,cpu-vendor-hooks";
	};

	qfprom: qfprom@221c8000 {
		compatible = "qcom,qfprom";
		reg = <0x221c8000 0x1000>;
		#address-cells = <1>;
		#size-cells = <1>;
		read-only;
		ranges;
	};

};

#include "anorak-qupv3.dtsi"
#include "diwali-gdsc.dtsi"

&qupv3_se6_2uart {
	status = "ok";
};

&cam_cc_bps_gdsc {
	clocks = <&gcc GCC_CAMERA_AHB_CLK>;
	clock-names = "ahb_clk";
	parent-supply = <&VDD_MM_MXC_VOTER_LEVEL>;
	reg = <0xadf0004 0x4>;
	status = "ok";
};

&cam_cc_ife_0_gdsc {
	clocks = <&gcc GCC_CAMERA_AHB_CLK>;
	clock-names = "ahb_clk";
	parent-supply = <&VDD_MM_MXC_VOTER_LEVEL>;
	reg = <0xadf1004 0x4>;
	status = "ok";
};

&cam_cc_ife_1_gdsc {
	clocks = <&gcc GCC_CAMERA_AHB_CLK>;
	clock-names = "ahb_clk";
	parent-supply = <&VDD_MM_MXC_VOTER_LEVEL>;
	reg = <0xadf2004 0x4>;
	status = "ok";
};

&cam_cc_ipe_0_gdsc {
	clocks = <&gcc GCC_CAMERA_AHB_CLK>;
	clock-names = "ahb_clk";
	parent-supply = <&VDD_MM_MXC_VOTER_LEVEL>;
	reg = <0xadf03b8 0x4>;
	status = "ok";
};

&cam_cc_titan_top_gdsc {
	clocks = <&gcc GCC_CAMERA_AHB_CLK>;
	clock-names = "ahb_clk";
	parent-supply = <&VDD_MM_MXC_VOTER_LEVEL>;
	reg = <0xadf4138 0x4>;
	status = "ok";
};

&disp_cc_mdss_core_gdsc {
	compatible = "regulator-fixed";
	status = "ok";
};

&disp_cc_mdss_core_int2_gdsc {
	compatible = "regulator-fixed";
	status = "ok";
};

&gcc_pcie_0_gdsc {
	parent-supply = <&VDD_CX_LEVEL>;
	status="ok";
};

&gcc_pcie_1_gdsc {
	parent-supply = <&VDD_CX_LEVEL>;
	reg = <0x1ad004 0x4>;
	qcom,support-hw-trigger;
	status="ok";
};

&gcc_pcie_2_gdsc {
	parent-supply = <&VDD_CX_LEVEL>;
	status="ok";
};

&gcc_ufs_phy_gdsc {
	parent-supply = <&VDD_CX_LEVEL>;
	status = "ok";
};

&gcc_usb30_prim_gdsc {
	parent-supply = <&VDD_CX_LEVEL>;
	status = "ok";
};

&hlos1_vote_mmnoc_mmu_tbu_hf0_gdsc {
	parent-supply = <&VDD_CX_LEVEL>;
	status = "ok";
};

&hlos1_vote_mmnoc_mmu_tbu_hf1_gdsc {
	parent-supply = <&VDD_CX_LEVEL>;
	status = "ok";
};

&hlos1_vote_mmnoc_mmu_tbu_hf2_gdsc {
	parent-supply = <&VDD_CX_LEVEL>;
	status = "ok";
};

&hlos1_vote_mmnoc_mmu_tbu_hf3_gdsc {
	parent-supply = <&VDD_CX_LEVEL>;
	status = "ok";
};

&hlos1_vote_mmnoc_mmu_tbu_hf4_gdsc {
	parent-supply = <&VDD_CX_LEVEL>;
	status = "ok";
};

&hlos1_vote_mmnoc_mmu_tbu_hf5_gdsc {
	parent-supply = <&VDD_CX_LEVEL>;
	status = "ok";
};

&hlos1_vote_mmnoc_mmu_tbu_sf0_gdsc {
	parent-supply = <&VDD_CX_LEVEL>;
	status = "ok";
};

&hlos1_vote_mmnoc_mmu_tbu_sf1_gdsc {
	parent-supply = <&VDD_CX_LEVEL>;
	status = "ok";
};

&hlos1_vote_turing_mmu_tbu0_gdsc {
	parent-supply = <&VDD_CX_LEVEL>;
	status = "ok";
};

&hlos1_vote_turing_mmu_tbu1_gdsc {
	parent-supply = <&VDD_CX_LEVEL>;
	status = "ok";
};

&gpu_cc_cx_gdsc {
	clocks = <&gcc GCC_GPU_CFG_AHB_CLK>;
	clock-names = "ahb_clk";
	parent-supply = <&VDD_CX_LEVEL>;
	status = "ok";
};

&gpu_cc_gx_gdsc {
	clocks = <&gcc GCC_GPU_CFG_AHB_CLK>;
	clock-names = "ahb_clk";
	parent-supply = <&VDD_GFX_MXC_VOTER_LEVEL>;
	status = "ok";
};

&video_cc_mvs0_gdsc {
	reg = <0xaaf809c 0x4>;
	clocks = <&gcc GCC_VIDEO_AHB_CLK>;
	clock-names = "ahb_clk";
	parent-supply = <&VDD_MM_MXC_VOTER_LEVEL>;
	status = "ok";
};

&video_cc_mvs0c_gdsc {
	reg = <0xaaf804c 0x4>;
	clocks = <&gcc GCC_VIDEO_AHB_CLK>;
	clock-names = "ahb_clk";
	parent-supply = <&VDD_MM_MXC_VOTER_LEVEL>;
	status = "ok";
};

&video_cc_mvs1_gdsc {
	reg = <0xaaf80c0 0x4>;
	clocks = <&gcc GCC_VIDEO_AHB_CLK>;
	clock-names = "ahb_clk";
	parent-supply = <&VDD_MM_MXC_VOTER_LEVEL>;
	status = "ok";
};

&video_cc_mvs1c_gdsc {
	reg = <0xaaf8074 0x4>;
	clocks = <&gcc GCC_VIDEO_AHB_CLK>;
	clock-names = "ahb_clk";
	parent-supply = <&VDD_MM_MXC_VOTER_LEVEL>;
	status = "ok";

};

#include "anorak-usb.dtsi"
#include "anorak-pinctrl.dtsi"
#include "anorak-stub-regulator.dtsi"
#include "anorak-dma-heaps.dtsi"
#include "ipcc-test.dtsi"
#include "anorak-pcie.dtsi"
#include "msm-arm-smmu-anorak.dtsi"
#include "anorak-coresight.dtsi"
#include "anorak-debug.dtsi"
